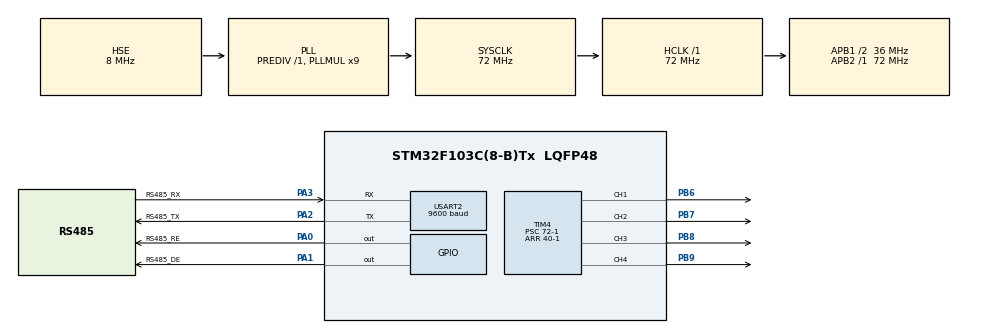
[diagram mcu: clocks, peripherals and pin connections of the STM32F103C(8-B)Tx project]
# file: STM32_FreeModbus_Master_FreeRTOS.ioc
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FREERTOS.INCLUDE_xEventGroupSetBitFromISR=1
FREERTOS.INCLUDE_xTimerPendFunctionCall=1
FREERTOS.Tasks01=defaultTask,0,128,StartDefaultTask,Default,NULL,Dynamic,NULL,NULL
FREERTOS.configUSE_TIMERS=1
Mcu.Family=STM32F1
Mcu.Name=STM32F103C(8-B)Tx
Mcu.Package=LQFP48
NVIC.PriorityGroup=NVIC_PRIORITYGROUP_4
NVIC.TIM2_IRQn=true\:5\:0\:false\:false\:true\:true\:true\:true
NVIC.TIM3_IRQn=true\:0\:0\:false\:false\:true\:false\:false\:true
NVIC.TimeBase=TIM3_IRQn
NVIC.TimeBaseIP=TIM3
NVIC.USART2_IRQn=true\:5\:0\:false\:false\:true\:true\:true\:true
PA0-WKUP.GPIO_Label=RS485_RE
PA0-WKUP.Signal=GPIO_Output
PA1.GPIO_Label=RS485_DE
PA1.Signal=GPIO_Output
PA13.Mode=Serial_Wire
PA13.Signal=SYS_JTMS-SWDIO
PA14.Mode=Serial_Wire
PA14.Signal=SYS_JTCK-SWCLK
PA2.GPIO_Label=RS485_TX
PA2.Mode=Asynchronous
PA2.Signal=USART2_TX
PA3.GPIO_Label=RS485_RX
PA3.Mode=Asynchronous
PA3.Signal=USART2_RX
PB6.Signal=S_TIM4_CH1
PB7.Signal=S_TIM4_CH2
PB8.Signal=S_TIM4_CH3
PB9.Signal=S_TIM4_CH4
PC14-OSC32_IN.Mode=LSE-External-Oscillator
PC14-OSC32_IN.Signal=RCC_OSC32_IN
PC15-OSC32_OUT.Mode=LSE-External-Oscillator
PC15-OSC32_OUT.Signal=RCC_OSC32_OUT
PD0-OSC_IN.Mode=HSE-External-Oscillator
PD0-OSC_IN.Signal=RCC_OSC_IN
PD1-OSC_OUT.Mode=HSE-External-Oscillator
PD1-OSC_OUT.Signal=RCC_OSC_OUT
ProjectManager.HeapSize=0x1000
ProjectManager.StackSize=0x1000
ProjectManager.TargetToolchain=STM32CubeIDE
RCC.AHBFreq_Value=72000000
RCC.APB1CLKDivider=RCC_HCLK_DIV2
RCC.APB1Freq_Value=36000000
RCC.APB1TimFreq_Value=72000000
RCC.APB2Freq_Value=72000000
RCC.APB2TimFreq_Value=72000000
RCC.HCLKFreq_Value=72000000
RCC.PLLMUL=RCC_PLL_MUL9
RCC.PLLSourceVirtual=RCC_PLLSOURCE_HSE
RCC.SYSCLKFreq_VALUE=72000000
RCC.SYSCLKSource=RCC_SYSCLKSOURCE_PLLCLK
RCC.USBFreq_Value=72000000
SH.S_TIM4_CH1.0=TIM4_CH1,PWM Generation1 CH1
SH.S_TIM4_CH2.0=TIM4_CH2,PWM Generation2 CH2
SH.S_TIM4_CH3.0=TIM4_CH3,PWM Generation3 CH3
SH.S_TIM4_CH4.0=TIM4_CH4,PWM Generation4 CH4
TIM2.AutoReloadPreload=TIM_AUTORELOAD_PRELOAD_ENABLE
TIM2.Period=80-1
TIM2.Prescaler=3600-1
TIM4.AutoReloadPreload=TIM_AUTORELOAD_PRELOAD_ENABLE
TIM4.Channel-PWM\ Generation1\ CH1=TIM_CHANNEL_1
TIM4.Channel-PWM\ Generation2\ CH2=TIM_CHANNEL_2
TIM4.Channel-PWM\ Generation3\ CH3=TIM_CHANNEL_3
TIM4.Channel-PWM\ Generation4\ CH4=TIM_CHANNEL_4
TIM4.Period=40-1
TIM4.Prescaler=72-1
USART2.BaudRate=9600
USART2.VirtualMode=VM_ASYNC
VP_FREERTOS_VS_CMSIS_V1.Mode=CMSIS_V1
VP_SYS_VS_tim3.Mode=TIM3
VP_TIM2_VS_ClockSourceINT.Mode=Internal
VP_TIM4_VS_ClockSourceINT.Mode=Internal
board=custom

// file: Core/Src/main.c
/* USER CODE BEGIN Header */
/**
  ******************************************************************************
  * @file           : main.c
  * @brief          : Main program body
  ******************************************************************************
  * @attention
  *
  * <h2><center>&copy; Copyright (c) 2020 STMicroelectronics.
  * All rights reserved.</center></h2>
  *
  * This software component is licensed by ST under BSD 3-Clause license,
  * the "License"; You may not use this file except in compliance with the
  * License. You may obtain a copy of the License at:
  *                        opensource.org/licenses/BSD-3-Clause
  *
  ******************************************************************************
  */
/* USER CODE END Header */
#include "main.h"
#include "cmsis_os.h"
#include "tim.h"
#include "usart.h"
#include "gpio.h"

void SystemClock_Config(void);
void MX_FREERTOS_Init(void);

int main(void)
{

  /* MCU Configuration--------------------------------------------------------*/

  /* Reset of all peripherals, Initializes the Flash interface and the Systick. */
  HAL_Init();

  /* Configure the system clock */
  SystemClock_Config();

  /* Initialize all configured peripherals */
  MX_GPIO_Init();
  MX_TIM4_Init();
  MX_USART2_UART_Init();
  MX_TIM2_Init();
  /* USER CODE BEGIN 2 */
  extern void Main_Thread_Add();
  extern void MB_Master_Thread_Add();
  MB_Master_Thread_Add();
  Main_Thread_Add();
  /* USER CODE END 2 */

  /* Call init function for freertos objects (in freertos.c) */
  MX_FREERTOS_Init();
  /* Start scheduler */
  osKernelStart();

  /* We should never get here as control is now taken by the scheduler */
  /* Infinite loop */
  while (1)
  {

  }
}

void SystemClock_Config(void)
{
  RCC_OscInitTypeDef RCC_OscInitStruct = {0};
  RCC_ClkInitTypeDef RCC_ClkInitStruct = {0};

  /** Initializes the RCC Oscillators according to the specified parameters
  * in the RCC_OscInitTypeDef structure.
  */
  RCC_OscInitStruct.OscillatorType = RCC_OSCILLATORTYPE_HSE;
  RCC_OscInitStruct.HSEState = RCC_HSE_ON;
  RCC_OscInitStruct.HSEPredivValue = RCC_HSE_PREDIV_DIV1;
  RCC_OscInitStruct.HSIState = RCC_HSI_ON;
  RCC_OscInitStruct.PLL.PLLState = RCC_PLL_ON;
  RCC_OscInitStruct.PLL.PLLSource = RCC_PLLSOURCE_HSE;
  RCC_OscInitStruct.PLL.PLLMUL = RCC_PLL_MUL9;
  if (HAL_RCC_OscConfig(&RCC_OscInitStruct) != HAL_OK)
  {
    Error_Handler();
  }
  /** Initializes the CPU, AHB and APB buses clocks
  */
  RCC_ClkInitStruct.ClockType = RCC_CLOCKTYPE_HCLK|RCC_CLOCKTYPE_SYSCLK
                              |RCC_CLOCKTYPE_PCLK1|RCC_CLOCKTYPE_PCLK2;
  RCC_ClkInitStruct.SYSCLKSource = RCC_SYSCLKSOURCE_PLLCLK;
  RCC_ClkInitStruct.AHBCLKDivider = RCC_SYSCLK_DIV1;
  RCC_ClkInitStruct.APB1CLKDivider = RCC_HCLK_DIV2;
  RCC_ClkInitStruct.APB2CLKDivider = RCC_HCLK_DIV1;

  if (HAL_RCC_ClockConfig(&RCC_ClkInitStruct, FLASH_LATENCY_2) != HAL_OK)
  {
    Error_Handler();
  }
}

 /**
  * @brief  Period elapsed callback in non blocking mode
  * @note   This function is called  when TIM3 interrupt took place, inside
  * HAL_TIM_IRQHandler(). It makes a direct call to HAL_IncTick() to increment
  * a global variable "uwTick" used as application time base.
  * @param  htim : TIM handle
  * @retval None
  */
void HAL_TIM_PeriodElapsedCallback(TIM_HandleTypeDef *htim)
{
  if (htim->Instance == TIM3) {
    HAL_IncTick();
  }
}

void Error_Handler(void)
{
  __disable_irq();
  while (1)
  {
  }
}

/************************ (C) COPYRIGHT STMicroelectronics *****END OF FILE****/

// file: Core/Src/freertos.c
/* USER CODE BEGIN Header */
/**
  ******************************************************************************
  * File Name          : freertos.c
  * Description        : Code for freertos applications
  ******************************************************************************
  * @attention
  *
  * <h2><center>&copy; Copyright (c) 2020 STMicroelectronics.
  * All rights reserved.</center></h2>
  *
  * This software component is licensed by ST under Ultimate Liberty license
  * SLA0044, the "License"; You may not use this file except in compliance with
  * the License. You may obtain a copy of the License at:
  *                             www.st.com/SLA0044
  *
  ******************************************************************************
  */
/* USER CODE END Header */

#include "FreeRTOS.h"
#include "task.h"
#include "main.h"
#include "cmsis_os.h"

osThreadId defaultTaskHandle;

void StartDefaultTask(void const * argument);

void MX_FREERTOS_Init(void); /* (MISRA C 2004 rule 8.1) */

/* GetIdleTaskMemory prototype (linked to static allocation support) */
void vApplicationGetIdleTaskMemory( StaticTask_t **ppxIdleTaskTCBBuffer, StackType_t **ppxIdleTaskStackBuffer, uint32_t *pulIdleTaskStackSize );

/* GetTimerTaskMemory prototype (linked to static allocation support) */
void vApplicationGetTimerTaskMemory( StaticTask_t **ppxTimerTaskTCBBuffer, StackType_t **ppxTimerTaskStackBuffer, uint32_t *pulTimerTaskStackSize );

/* USER CODE BEGIN GET_IDLE_TASK_MEMORY */
static StaticTask_t xIdleTaskTCBBuffer;
static StackType_t xIdleStack[configMINIMAL_STACK_SIZE];

void vApplicationGetIdleTaskMemory( StaticTask_t **ppxIdleTaskTCBBuffer, StackType_t **ppxIdleTaskStackBuffer, uint32_t *pulIdleTaskStackSize )
{
  *ppxIdleTaskTCBBuffer = &xIdleTaskTCBBuffer;
  *ppxIdleTaskStackBuffer = &xIdleStack[0];
  *pulIdleTaskStackSize = configMINIMAL_STACK_SIZE;
  /* place for user code */
}
/* USER CODE END GET_IDLE_TASK_MEMORY */

/* USER CODE BEGIN GET_TIMER_TASK_MEMORY */
static StaticTask_t xTimerTaskTCBBuffer;
static StackType_t xTimerStack[configTIMER_TASK_STACK_DEPTH];

void vApplicationGetTimerTaskMemory( StaticTask_t **ppxTimerTaskTCBBuffer, StackType_t **ppxTimerTaskStackBuffer, uint32_t *pulTimerTaskStackSize )
{
  *ppxTimerTaskTCBBuffer = &xTimerTaskTCBBuffer;
  *ppxTimerTaskStackBuffer = &xTimerStack[0];
  *pulTimerTaskStackSize = configTIMER_TASK_STACK_DEPTH;
  /* place for user code */
}
/* USER CODE END GET_TIMER_TASK_MEMORY */

void MX_FREERTOS_Init(void) {

  /* Create the thread(s) */
  /* definition and creation of defaultTask */
  osThreadDef(defaultTask, StartDefaultTask, osPriorityNormal, 0, 128);
  defaultTaskHandle = osThreadCreate(osThread(defaultTask), NULL);

}

void StartDefaultTask(void const * argument)
{
  for(;;)
  {
    osDelay(1);
  }
}

/************************ (C) COPYRIGHT STMicroelectronics *****END OF FILE****/
